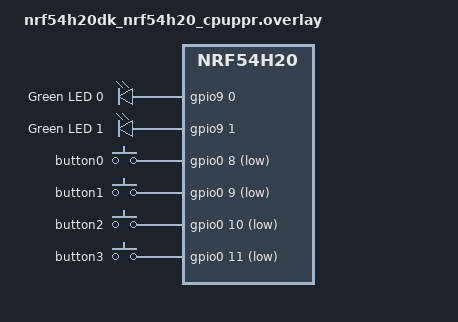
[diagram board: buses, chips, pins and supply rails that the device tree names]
/*
 * Copyright (c) 2024 Nordic Semiconductor ASA
 *
 * SPDX-License-Identifier: LicenseRef-Nordic-5-Clause
 */

/* Enable IPC. */
&cpuppr_vevif {
	status = "okay";
};

&cpuapp_bellboard {
	status = "okay";
};

ipc1: &cpuapp_cpuppr_ipc {
	status = "okay";
};


/* Enable GPIO support. */
&gpiote130 {
	status = "okay";
};

&gpio0 {
	status = "okay";
};

&gpio9 {
	status = "okay";
};

/ {
	/* Redefine leds to fit CAF requirements. */
	/delete-node/ leds;

	leds0 {
		compatible = "gpio-leds";
		status = "okay";
		label = "System State LED";

		led0: led_0 {
			gpios = < &gpio9 0 GPIO_ACTIVE_HIGH >;
			label = "Green LED 0";
		};
	};

	leds1 {
		compatible = "gpio-leds";
		status = "okay";
		label = "Peer State LED";

		led1: led_1 {
			gpios = < &gpio9 1 GPIO_ACTIVE_HIGH >;
			label = "Green LED 1";
		};
	};

	leds2 {
		compatible = "gpio-leds";
		status = "disabled";
		label = "Unused LED 2";

		led2: led_2 {
			gpios = < &gpio9 2 GPIO_ACTIVE_HIGH >;
			label = "Green LED 2";
		};
	};

	leds3 {
		compatible = "gpio-leds";
		status = "disabled";
		label = "Unused LED 3";

		led3: led_3 {
			gpios = < &gpio9 3 GPIO_ACTIVE_HIGH >;
			label = "Green LED 3";
		};
	};

	/* Define buttons to use them in "buttons_def.h" header file. */
	buttons {
		compatible = "gpio-keys";
		button0: button_0 {
			gpios = <&gpio0 8 (GPIO_PULL_UP | GPIO_ACTIVE_LOW)>;
		};

		button1: button_1 {
			gpios = <&gpio0 9 (GPIO_PULL_UP | GPIO_ACTIVE_LOW)>;
		};

		button2: button_2 {
			gpios = <&gpio0 10 (GPIO_PULL_UP | GPIO_ACTIVE_LOW)>;
		};

		button3: button_3 {
			gpios = <&gpio0 11 (GPIO_PULL_UP | GPIO_ACTIVE_LOW)>;
		};
	};
};
